# CY8C3246PVI_147 register map
File version: 0.1
Registers are 8-bit, read-write, no defined reset value unless marked. A register's access mark holds for its fields unless they carry their own. Offsets are from the block's base; [hi:lo] are bit positions; 'fields as' and 'values as' point back to an identical list.

## I2C
Base 0x00000000
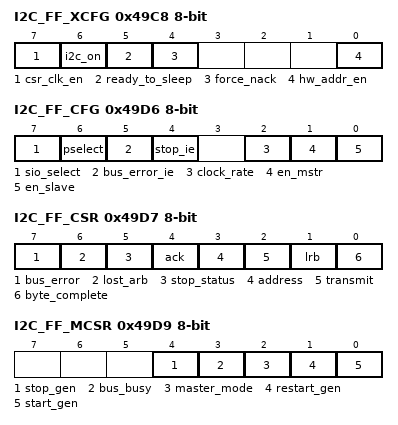
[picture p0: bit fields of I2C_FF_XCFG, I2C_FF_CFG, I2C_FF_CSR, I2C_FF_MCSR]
0x49C8 I2C_FF_XCFG — I2C Extended Configuration Register
  [7] csr_clk_en — This bit is used for gating system clock for the blocks core logic that is not associated with AHB interface. Clock is made available to the core logic only when this bit is set to 1 and the input pin ext_clk_en is also active. If either of them is not active, the blocks core logic does not receive the system clock.
  [6] i2c_on — This bit should be set by the user during initial block configuration if the user wants to use the I2C block as wake-up source. Only when this bit set along with other bits mentioned in the sleep mode section, the I2C wakes up system from sleep on address match.
  [5] ready_to_sleep ro — Once the user sets the force_nack bit, the I2C block sets this bit if I2C is not busy or it waits for ongoing transaction to be completed and then sets this bit. As long as this bit is set, the I2C block is going to nack all the transactions.Clearing force_nack bit automatically clears this bit. HW clears this bit automatically on assertion of PD (Power Down)
  [4] force_nack — This bit must be set by the user before putting the device to sleep and wait for ready_to_sleep status bit to be set. This can be cleared by user by writing '0' and the HW clears it automatically on assertion of PD(Power Down)
  [0] hw_addr_en — When this bit is set to a '1', hardware address compare is enabled. On an address match, an interrupt is generated, CSR register bit 3 is set, and the clock is stalled until the CPU writes a 0 into the CSR register bit 3. The address is automatically ACKed on a match. On an address mismatch,no interrupt is generated, clock is not stalled, and bit 3 in the CSR register is set. The CPU must write a 0 into the CSR register bit 3 to clear it. The address is automatically NACKed on a mismatch. You must configure the compare address in the ADR register. When this bit is set to a '0', software address compare is enabled. An interrupt is generated, the clock is stalled, and CSR register bit 3 is set when the received address byte is available in the Data register; to enable the CPU to do a firmware address compare. The clock is stalled until the CPU writes a 0 into the CSR register bit 3. The functionality of this bit is independent of the data buffering mode.
0x49CA I2C_FF_ADDR — I2C Slave Adddress Register
  [6:0] slave_address — These seven bits hold the slave's own device address. These bits are held zero if I2C_CFG.en_mstr and I2C_CFG.en_slave are both zero.
0x49D6 I2C_FF_CFG — I2C Configuration Register
  [7] sio_select — I2C Pin Select for SCL/SDA lines from SIO1/SIO2, 0 = SCL and SDA lines get their inputs from SIO1 module.sclk_str1 and sda_ack1 are driven to SIO1 module and they get asserted once device wakes up from sleep. 1 = SCL and SDA lines get their inputs from SIO2 module. sclk_str2 and sda_ack2 are driven to SIO2 module and they get asserted once device wakes up from sleep. This bit is valid only when I2C.CFG[6] is asserted.
  [6] pselect — I2C Pin Select for SCL/SDA lines from GPIO/SIO, 0 = SCL and SDA lines get their inputs from GPIO module.sclk_str0 and sda_ack0 are driven to GPIO module and they get asserted once device wakes up from sleep. 1 = SCL and SDA lines get their inputs from one of the SIO Blocks that is chosen based on the configuration of bit I2C.CFG[7]
  [5] bus_error_ie — Bus Error Interrupt Enable 0 disabled 1 enabled. An interrupt is generated on the detection of a Bus error condition.
  [4] stop_ie — Stop Interrupt Enable 0 disabled 1 enabled. An interrupt is generated on the detection of a Stop condition.
  [2] clock_rate — 0 Samples/bit is 16, 1 Samples/bit is 32
  [1] en_mstr — Enables master mode for the device
  [0] en_slave — Enables Slave mode for the device
0x49D7 I2C_FF_CSR — I2C Control and Status Register
  [7] bus_error — It must be cleared by firmware by writing a '0' to the bit position. It is never cleared by the hardware. 1 a misplaced Start or Stop condition was detected. This bit is held zero if I2C_CFG.en_mstr and I2C_CFG.en_slave are both zero.
  [6] lost_arb — This bit is set immediately on lost arbitration; however, it does not cause an interrupt. This status may be checked after the following Byte Complete interrupt. Any Start detect or a write to the Start or Restart generate bits (MCSR register), when operating in Master mode, will also clear the bit. 1 lost Arbitration. This bit is held zero if I2C_CFG.en_mstr is zero.
  [5] stop_status — It must be cleared by firmware with write of '0' to the bit position. It is never cleared by the hardware. 1 a Stop condition was detected. This bit is held zero if I2C_CFG.en_mstr and I2C_CFG.en_slave are both zero.
  [4] ack — Acknowledge Out. Bit is automatically cleared by hardware on a Byte Complete event. 0 nack the last received byte. 1 ack the last received byte
  [3] address — It must be cleared by firmware with write of '0' to the bit position. 1 the received byte is a slave address. This bit is held zero if I2C_CFG.en_mstr and I2C_CFG.en_slave are both zero
  [2] transmit — Bit is set by firmware to define the direction of the byte transfer. Any Start detect will clear the bit. 0 receive mode 1 transmit mode. This bit is held zero if I2C_CFG.en_mstr and I2C_CFG.en_slave are both zero.
  [1] lrb — Last Received Bit. The value of the 9th bit in a Transmit sequence, which is the acknowledge bit from the receiver. Any Start detect or a write to the Start or Restart generate bits, when operating in Master mode, will also clear the bit. 0 last transmitted byte was ACK'ed by the receiver. 1 last transmitted byte was NACK'ed by the receiver. This bit is held zero if I2C_CFG.en_mstr and I2C_CFG.en_slave are both zero.
  [0] byte_complete — Transmit/Receive Mode: 0 no completed transmit/receive since last cleared by firmware. Any Start detect or a write to the start or Restart generate bits, when operating in Master mode, will also clear the bit. Transmit mode: 1 eight bits of data have been transmitted and an ACK or NACK has been received. Receive mode: 1 eight bits of data have been received. This bit is held zero if I2C_CFG.en_mstr and I2C_CFG.en_slave are both zero.
0x49D8 I2C_FF_DATA — I2C Data Register
  [7:0] data — Read received data or write data to transmit. These bits are held zero if I2C_CFG.en_mstr and I2C_CFG.en_slave are both zero.
0x49D9 I2C_FF_MCSR — Master Control and Status Register: I2C_MCSR
  [4] stop_gen — This bit is set only for master transmitter and used at the end of byte transfer. After byte complete status is set, if this bit is set followed by the Transmit bit in I2C.CSR register, Stop condition is generated after byte complete. This bit is automatically reset to 0 after the Stop, start or Restart has been generated. During data phase, if Stop Gen bit is set to 0, clearing the Transmit bit in I2C.CSR register will also generate a Stop condition. This bit is held zero if I2C_CFG.en_mstr and I2C_CFG.en_slave are both zero.
  [3] bus_busy ro — This bit is set to the following. 0 when a Stop condition is detected (from any bus master). 1 when a Start condition is detected (from any bus master). This bit is held zero if I2C_CFG.en_mstr and I2C_CFG.en_slave are both zero.
  [2] master_mode ro — This bit is set/cleared by hardware when the device is operating as a master. 0 stop condition detected, generated by this device. 1 start condition detected, generated by this device. This bit is held zero if I2C_CFG.en_mstr and I2C_CFG.en_slave are both zero.
  [1] restart_gen — This bit is cleared by hardware when the Restart generation is complete. 0 restart generation complete. 1 generate a Restart condition. This bit is held zero if I2C_CFG.en_mstr and I2C_CFG.en_slave are both zero.
  [0] start_gen — This bit is cleared by hardware when the Start generation is complete. 0 start generation complete. 1 generate a Start condition and send a byte (address) to the I2C bus, if bus is not busy. This bit is held zero if I2C_CFG.en_mstr and I2C_CFG.en_slave are both zero.
0x49DB I2C_FF_CLK_DIV1 — I2C Clock Divide Factor Register-1
  [7:0] Div — The configuration of this register along with that in register CLK_DIV2 defines the factor by which the SYSCLK will be divided in the I2C block. These bits are held zero if I2C_CFG.en_mstr and I2C_CFG.en_slave are both zero.
0x49DC I2C_FF_CLK_DIV2 — I2C Clock Divide Factor Register-2
  [1:0] Div — The configuration of this register along with that in register CLK_DIV1 defines the factor by whichthe SYSCLK will be divided in the I2C block. These bits are held zero if I2C_CFG.en_mstr and I2C_CFG.en_slave are both zero.

## I2S
Base 0x00000000
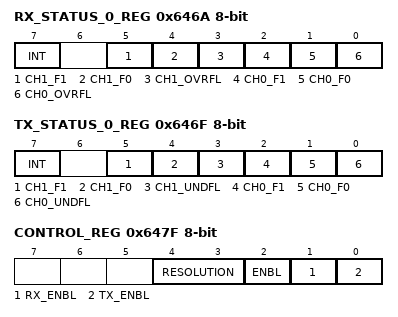
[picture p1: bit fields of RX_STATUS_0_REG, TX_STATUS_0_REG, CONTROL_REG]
0x646A RX_STATUS_0_REG
  [7] INT ro — Interrupt bit
  [5] CH1_F1 ro — Stereo channel 1 FIFO 1 state
    0=EMPTY; 1=NOT_EMPTY
  [4] CH1_F0 ro — Stereo channel 1 FIFO 0 state
    0=EMPTY; 1=NOT_EMPTY
  [3] CH1_OVRFL ro — Stereo channel 1 FIFO overflow
    0=NO_OVERFLOW; 1=OVERFLOW
  [2] CH0_F1 ro — Stereo channel 0 FIFO 1 state
    0=EMPTY; 1=NOT_EMPTY
  [1] CH0_F0 ro — Stereo channel 0 FIFO 0 state
    0=EMPTY; 1=NOT_EMPTY
  [0] CH0_OVRFL ro — Stereo channel 0 FIFO overflow
    0=NO_OVERFLOW; 1=OVERFLOW
0x646F TX_STATUS_0_REG
  [7] INT ro — Interrupt bit
  [5] CH1_F1 ro — Stereo channel 1 FIFO 1 state
    0=FULL; 1=NOT_FULL
  [4] CH1_F0 ro — Stereo channel 1 FIFO 0 state
    0=FULL; 1=NOT_FULL
  [3] CH1_UNDFL ro — Stereo channel 1 FIFO underflow
    0=NO_UNDERFLOW; 1=UNDERFLOW
  [2] CH0_F1 ro — Stereo channel 0 FIFO 1 state
    0=FULL; 1=NOT_FULL
  [1] CH0_F0 ro — Stereo channel 0 FIFO 0 state
    0=FULL; 1=NOT_FULL
  [0] CH0_UNDFL ro — Stereo channel 0 FIFO underflow
    0=NO_UNDERFLOW; 1=UNDERFLOW
0x647F CONTROL_REG
  [4:3] RESOLUTION — Specifies data bits value. Applicable only if dynamic bit resolution is selected.
    0=8_BIT; 1=16_BIT; 2=24_BIT; 3=32_BIT
  [2] ENBL — Starts the generation of the WS and SCK outputs.
    1=ENABLED; 0=DISABLED
  [1] RX_ENBL — Enables Rx direction. Applicable only if Rx direction presents for the component.
    1=ENABLED; 0=DISABLED
  [0] TX_ENBL — Enables Tx direction. Applicable only if Tx direction presents for the component.
    1=ENABLED; 0=DISABLED

## USBFS_EP8_DMA_Done_SR
Base 0x00006466
0x00 USBFS_EP8_DMA_Done_SR_STATUS_REG
0x20 USBFS_EP8_DMA_Done_SR_MASK_REG
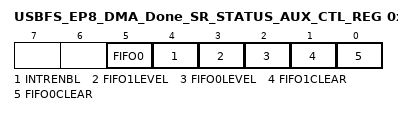
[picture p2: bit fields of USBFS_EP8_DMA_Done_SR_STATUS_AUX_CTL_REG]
0x30 USBFS_EP8_DMA_Done_SR_STATUS_AUX_CTL_REG
  [5] FIFO0 — FIFO0 clear
    1=ENABLED (Enable counter); 0=DISABLED (Disable counter)
  [4] INTRENBL — Enables or disables the Interrupt
    1=ENABLED (Interrupt enabled); 0=DISABLED (Interrupt disabled)
  [3] FIFO1LEVEL — FIFO level
    1=ENABLED (FIFO LVL: input mode: FIFO at least 1/2 empty; output mode: FIFO at least 1/2 full); 0=DISABLED (FIFO LVL: input mode: FIFO not full; output mode: FIFO not empty)
  [2] FIFO0LEVEL — FIFO level
    values as FIFO1LEVEL
  [1] FIFO1CLEAR — FIFO clear
    1=ENABLED (Clear FIFO state); 0=DISABLED (Normal FIFO operation)
  [0] FIFO0CLEAR — FIFO clear
    values as FIFO1CLEAR

## USBFS_EP17_DMA_Done_SR
Base 0x00006467
Registers as USBFS_EP8_DMA_Done_SR (with USBFS_EP8_DMA_Done_SR read as USBFS_EP17_DMA_Done_SR).

## Status
Base 0x0000646C
Registers as USBFS_EP8_DMA_Done_SR (with USBFS_EP8_DMA_Done_SR read as Status).
